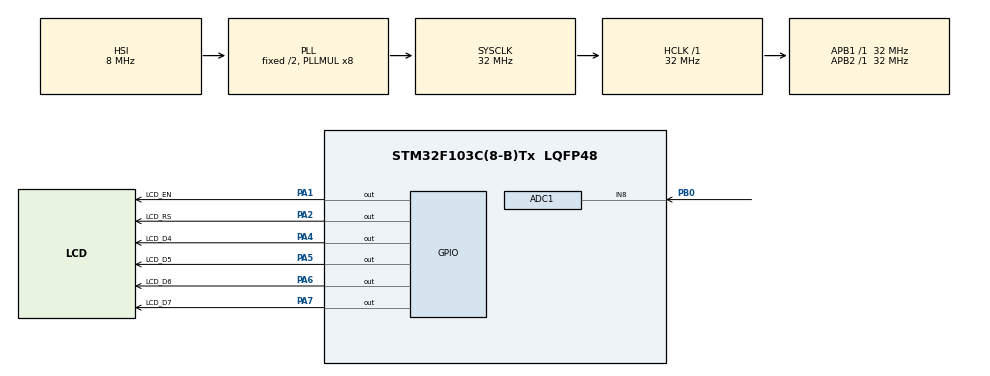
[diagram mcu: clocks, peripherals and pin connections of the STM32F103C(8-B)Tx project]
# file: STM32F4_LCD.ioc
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ADC1.Channel-3\#ChannelRegularConversion=ADC_CHANNEL_8
ADC1.ContinuousConvMode=ENABLE
ADC1.EnableRegularConversion=ENABLE
ADC1.NbrOfConversionFlag=1
ADC1.Rank-3\#ChannelRegularConversion=1
ADC1.SamplingTime-3\#ChannelRegularConversion=ADC_SAMPLETIME_1CYCLE_5
ADC1.master=1
Mcu.Family=STM32F1
Mcu.Name=STM32F103C(8-B)Tx
Mcu.Package=LQFP48
NVIC.PriorityGroup=NVIC_PRIORITYGROUP_4
PA1.GPIO_Label=LCD_EN
PA1.Signal=GPIO_Output
PA13.Mode=Serial_Wire
PA13.Signal=SYS_JTMS-SWDIO
PA14.Mode=Serial_Wire
PA14.Signal=SYS_JTCK-SWCLK
PA2.GPIO_Label=LCD_RS
PA2.Signal=GPIO_Output
PA4.GPIO_Label=LCD_D4
PA4.Signal=GPIO_Output
PA5.GPIO_Label=LCD_D5
PA5.Signal=GPIO_Output
PA6.GPIO_Label=LCD_D6
PA6.Signal=GPIO_Output
PA7.GPIO_Label=LCD_D7
PA7.Signal=GPIO_Output
PB0.Signal=ADCx_IN8
ProjectManager.HeapSize=0x200
ProjectManager.StackSize=0x400
ProjectManager.TargetToolchain=STM32CubeIDE
RCC.ADCPresc=RCC_ADCPCLK2_DIV4
RCC.AHBFreq_Value=32000000
RCC.APB1Freq_Value=32000000
RCC.APB1TimFreq_Value=32000000
RCC.APB2Freq_Value=32000000
RCC.APB2TimFreq_Value=32000000
RCC.HCLKFreq_Value=32000000
RCC.PLLMUL=RCC_PLL_MUL8
RCC.SYSCLKFreq_VALUE=32000000
RCC.SYSCLKSource=RCC_SYSCLKSOURCE_PLLCLK
RCC.USBFreq_Value=32000000
SH.ADCx_IN8.0=ADC1_IN8,IN8
board=custom

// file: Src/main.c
/* USER CODE BEGIN Header */
/**
  ******************************************************************************
  * @file           : main.c
  * @brief          : Main program body
  ******************************************************************************
  * @attention
  *
  * Copyright (c) 2022 STMicroelectronics.
  * All rights reserved.
  *
  * This software is licensed under terms that can be found in the LICENSE file
  * in the root directory of this software component.
  * If no LICENSE file comes with this software, it is provided AS-IS.
  *
  ******************************************************************************
  */
/* USER CODE END Header */
#include "main.h"

/* USER CODE BEGIN Includes */
#include "lcd.h"
#include "stdlib.h"
#include "stdio.h"

ADC_HandleTypeDef hadc1;

/* USER CODE BEGIN PV */
uint16_t	AdcValue;
float	Temperature;

char str[16];
/* USER CODE END PV */
void SystemClock_Config(void);
static void MX_GPIO_Init(void);
static void MX_ADC1_Init(void);

int main(void)
{
  /* MCU Configuration--------------------------------------------------------*/

  /* Reset of all peripherals, Initializes the Flash interface and the Systick. */
  HAL_Init();

  /* Configure the system clock */
  SystemClock_Config();

  /* Initialize all configured peripherals */
  MX_GPIO_Init();
  MX_ADC1_Init();
  /* USER CODE BEGIN 2 */
  lcd_init(_LCD_4BIT, _LCD_FONT_5x8, _LCD_2LINE);
  HAL_ADC_Start(&hadc1);

  /* USER CODE END 2 */

  /* Infinite loop */
  while (1)
  {

    /* USER CODE BEGIN 3 */
	  AdcValue=0;
	  for(int i=0;i<20;i++)
		  AdcValue += HAL_ADC_GetValue(&hadc1)/20;
	  Temperature = (float)((float)AdcValue/4095)*3300;
	  Temperature *= 0.1;
	  sprintf(str,"%2.2f'C",Temperature);
	  lcd_print(1,1,"Temperature");
	  lcd_print(2,1,str);
	  HAL_Delay(250);

  }
  /* USER CODE END 3 */
}

void SystemClock_Config(void)
{
  RCC_OscInitTypeDef RCC_OscInitStruct = {0};
  RCC_ClkInitTypeDef RCC_ClkInitStruct = {0};
  RCC_PeriphCLKInitTypeDef PeriphClkInit = {0};

  /** Initializes the RCC Oscillators according to the specified parameters
  * in the RCC_OscInitTypeDef structure.
  */
  RCC_OscInitStruct.OscillatorType = RCC_OSCILLATORTYPE_HSI;
  RCC_OscInitStruct.HSIState = RCC_HSI_ON;
  RCC_OscInitStruct.HSICalibrationValue = RCC_HSICALIBRATION_DEFAULT;
  RCC_OscInitStruct.PLL.PLLState = RCC_PLL_ON;
  RCC_OscInitStruct.PLL.PLLSource = RCC_PLLSOURCE_HSI_DIV2;
  RCC_OscInitStruct.PLL.PLLMUL = RCC_PLL_MUL8;
  if (HAL_RCC_OscConfig(&RCC_OscInitStruct) != HAL_OK)
  {
    Error_Handler();
  }
  /** Initializes the CPU, AHB and APB buses clocks
  */
  RCC_ClkInitStruct.ClockType = RCC_CLOCKTYPE_HCLK|RCC_CLOCKTYPE_SYSCLK
                              |RCC_CLOCKTYPE_PCLK1|RCC_CLOCKTYPE_PCLK2;
  RCC_ClkInitStruct.SYSCLKSource = RCC_SYSCLKSOURCE_PLLCLK;
  RCC_ClkInitStruct.AHBCLKDivider = RCC_SYSCLK_DIV1;
  RCC_ClkInitStruct.APB1CLKDivider = RCC_HCLK_DIV1;
  RCC_ClkInitStruct.APB2CLKDivider = RCC_HCLK_DIV1;

  if (HAL_RCC_ClockConfig(&RCC_ClkInitStruct, FLASH_LATENCY_1) != HAL_OK)
  {
    Error_Handler();
  }
  PeriphClkInit.PeriphClockSelection = RCC_PERIPHCLK_ADC;
  PeriphClkInit.AdcClockSelection = RCC_ADCPCLK2_DIV4;
  if (HAL_RCCEx_PeriphCLKConfig(&PeriphClkInit) != HAL_OK)
  {
    Error_Handler();
  }
}

static void MX_ADC1_Init(void)
{

  ADC_ChannelConfTypeDef sConfig = {0};

  /** Common config
  */
  hadc1.Instance = ADC1;
  hadc1.Init.ScanConvMode = ADC_SCAN_DISABLE;
  hadc1.Init.ContinuousConvMode = ENABLE;
  hadc1.Init.DiscontinuousConvMode = DISABLE;
  hadc1.Init.ExternalTrigConv = ADC_SOFTWARE_START;
  hadc1.Init.DataAlign = ADC_DATAALIGN_RIGHT;
  hadc1.Init.NbrOfConversion = 1;
  if (HAL_ADC_Init(&hadc1) != HAL_OK)
  {
    Error_Handler();
  }
  /** Configure Regular Channel
  */
  sConfig.Channel = ADC_CHANNEL_8;
  sConfig.Rank = ADC_REGULAR_RANK_1;
  sConfig.SamplingTime = ADC_SAMPLETIME_1CYCLE_5;
  if (HAL_ADC_ConfigChannel(&hadc1, &sConfig) != HAL_OK)
  {
    Error_Handler();
  }

}

static void MX_GPIO_Init(void)
{
  GPIO_InitTypeDef GPIO_InitStruct = {0};

  /* GPIO Ports Clock Enable */
  __HAL_RCC_GPIOA_CLK_ENABLE();
  __HAL_RCC_GPIOB_CLK_ENABLE();

  /*Configure GPIO pin Output Level */
  HAL_GPIO_WritePin(GPIOA, LCD_EN_Pin|LCD_RS_Pin|LCD_D4_Pin|LCD_D5_Pin
                          |LCD_D6_Pin|LCD_D7_Pin, GPIO_PIN_RESET);

  /*Configure GPIO pins : LCD_EN_Pin LCD_RS_Pin LCD_D4_Pin LCD_D5_Pin
                           LCD_D6_Pin LCD_D7_Pin */
  GPIO_InitStruct.Pin = LCD_EN_Pin|LCD_RS_Pin|LCD_D4_Pin|LCD_D5_Pin
                          |LCD_D6_Pin|LCD_D7_Pin;
  GPIO_InitStruct.Mode = GPIO_MODE_OUTPUT_PP;
  GPIO_InitStruct.Pull = GPIO_NOPULL;
  GPIO_InitStruct.Speed = GPIO_SPEED_FREQ_LOW;
  HAL_GPIO_Init(GPIOA, &GPIO_InitStruct);

}

void Error_Handler(void)
{
  __disable_irq();
  while (1)
  {
  }
}
